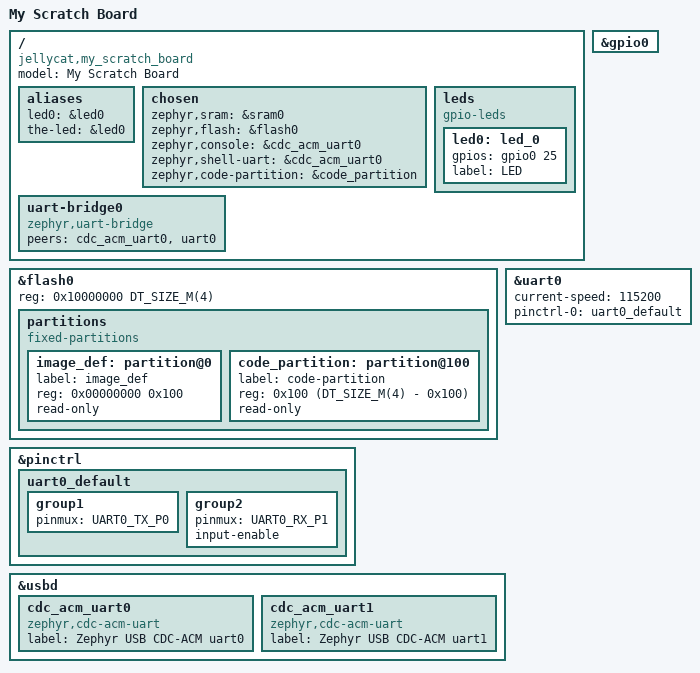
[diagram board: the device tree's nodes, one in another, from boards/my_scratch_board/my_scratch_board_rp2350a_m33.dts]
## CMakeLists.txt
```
cmake_minimum_required(VERSION 3.20.0)


list(APPEND BOARD_ROOT ${CMAKE_CURRENT_SOURCE_DIR})

find_package(Zephyr REQUIRED)
project(my_zephyr_app)

zephyr_include_directories(include)

add_subdirectory(drivers/our_driver)
target_sources(app PRIVATE src/main.cpp)
```

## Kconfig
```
config APP_HEARTBEAT_PERIOD_MS
  int "APP_HEARTBEAT_PERIOD_MS"
    default 500
    range 100 2000
config BLINK_SLEEP_TIME_MS
  int "BLINK_SLEEP_TIME_MS"
    default 500
    range 100 2000

source "Kconfig.zephyr"
rsource "drivers/our_driver/Kconfig"
```

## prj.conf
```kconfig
CONFIG_GPIO=y
CONFIG_LOG=y
CONFIG_BLINK_SLEEP_TIME_MS=500
CONFIG_OUR_DRIVER=y
```

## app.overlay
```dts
/ {
	our_driver0: our_driver {
		compatible = "our,driver";
		led-gpios = <&led0>;
	};
};
```

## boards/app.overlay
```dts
/ {
    aliases {
	app-led = &led0;
    };
};
```

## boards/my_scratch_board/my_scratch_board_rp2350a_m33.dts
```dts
/dts-v1/;

#include <zephyr/dt-bindings/pinctrl/rpi-pico-rp2350a-pinctrl.h>

#include <raspberrypi/rpi_pico/rp2350a.dtsi>
#include <raspberrypi/rpi_pico/m33.dtsi>

/ {
	model = "My Scratch Board";
	compatible = "jellycat,my_scratch_board";

	aliases {
		led0 = &led0;
		the-led = &led0;
	};

	chosen {
		zephyr,sram = &sram0;
		zephyr,flash = &flash0;
		zephyr,console = &cdc_acm_uart0;
		zephyr,shell-uart = &cdc_acm_uart0;
		zephyr,code-partition = &code_partition;
	};

	leds {
		compatible = "gpio-leds";
		led0: led_0 {
			gpios = <&gpio0 25 GPIO_ACTIVE_HIGH>;
			label = "LED";
		};
	};
	uart-bridge0 {
		compatible = "zephyr,uart-bridge";
		peers = <&cdc_acm_uart0 &uart0>;
	};

};

&gpio0 {
	status = "okay";
};

&flash0 {
	reg = <0x10000000 DT_SIZE_M(4)>;

	partitions {
		compatible = "fixed-partitions";
		#address-cells = <1>;
		#size-cells = <1>;

		/* Reserved memory for an image definition block. The block is much
		 * smaller than 256 bytes, but in practice the linker places the vector
		 * table at a much larger alignment offset.
		 */
		image_def: partition@0 {
			label = "image_def";
			reg = <0x00000000 0x100>;
			read-only;
		};

		/*
		 * Usable flash. Starts at 0x100, after the image definition block.
		 * The partition size is 4MB minus the 0x100 bytes taken by the
		 * image definition.
		 */
		code_partition: partition@100 {
			label = "code-partition";
			reg = <0x100 (DT_SIZE_M(4) - 0x100)>;
			read-only;
		};
	};
};

&pinctrl {
	uart0_default: uart0_default {
		group1 {
			pinmux = <UART0_TX_P0>;
		};
		group2 {
			pinmux = <UART0_RX_P1>;
			input-enable;
		};
	};
};

&uart0 {
	current-speed = <115200>;
	status = "okay";
	pinctrl-0 = <&uart0_default>;
	pinctrl-names = "default";
};

&usbd {
	status = "okay";

	cdc_acm_uart0: cdc_acm_uart0 {
		compatible = "zephyr,cdc-acm-uart";
		label = "Zephyr USB CDC-ACM uart0";
	};

	cdc_acm_uart1: cdc_acm_uart1 {
		compatible = "zephyr,cdc-acm-uart";
		label = "Zephyr USB CDC-ACM uart1";
	};
};
```

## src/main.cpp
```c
#include <zephyr/drivers/gpio.h>
#include <zephyr/kernel.h>
#include <zephyr/logging/log.h>
#include <zephyr/drivers/sensor.h>
#include <our_driver/our_driver.h>

/* The devicetree node identifier for the "led0" alias. */
// #define LED_NODE DT_ALIAS(led0)

// static const struct gpio_dt_spec led = GPIO_DT_SPEC_GET(LED_NODE, gpios);

LOG_MODULE_REGISTER(main, LOG_LEVEL_INF);

// namespace 
// {
//     void test() {
//         const struct device* driver = DEVICE_DT_GET(DT_NODELABEL(our_driver0));
//         struct sensor_value val;
//         auto ret = sensor_channel_get(driver, SENSOR_CHAN_AMBIENT_TEMP, &val);
//         LOG_INF("Channel ret %d", ret);
//     }
    
// } // namespace 

int main(void)
{
    // bool led_state = true;

    // if (!gpio_is_ready_dt(&led)) return 0;

    // if (gpio_pin_configure_dt(&led, GPIO_OUTPUT_ACTIVE) < 0) return 0;
    const struct device* driver = DEVICE_DT_GET(DT_NODELABEL(our_driver0));
    if (!device_is_ready(driver)) {
        LOG_INF("Sensor driver failed initialization\n");
        return 0;
    }
    struct sensor_value val;
    custom_driver_reset(driver);
    while (1) {
        // if (gpio_pin_toggle_dt(&led) < 0) return 0;
        
        // led_state = !led_state;
        // LOG_INF("LED state: %s", led_state ? "ON" : "OFF");
        sensor_channel_get(driver, SENSOR_CHAN_AMBIENT_TEMP, &val);
        k_msleep(CONFIG_BLINK_SLEEP_TIME_MS);
        sensor_sample_fetch(driver);
        k_msleep(CONFIG_BLINK_SLEEP_TIME_MS);
        sensor_attr_set(driver, SENSOR_CHAN_AMBIENT_TEMP, SENSOR_ATTR_COMMON_COUNT, &val);
    }
    return 0;
}
```
